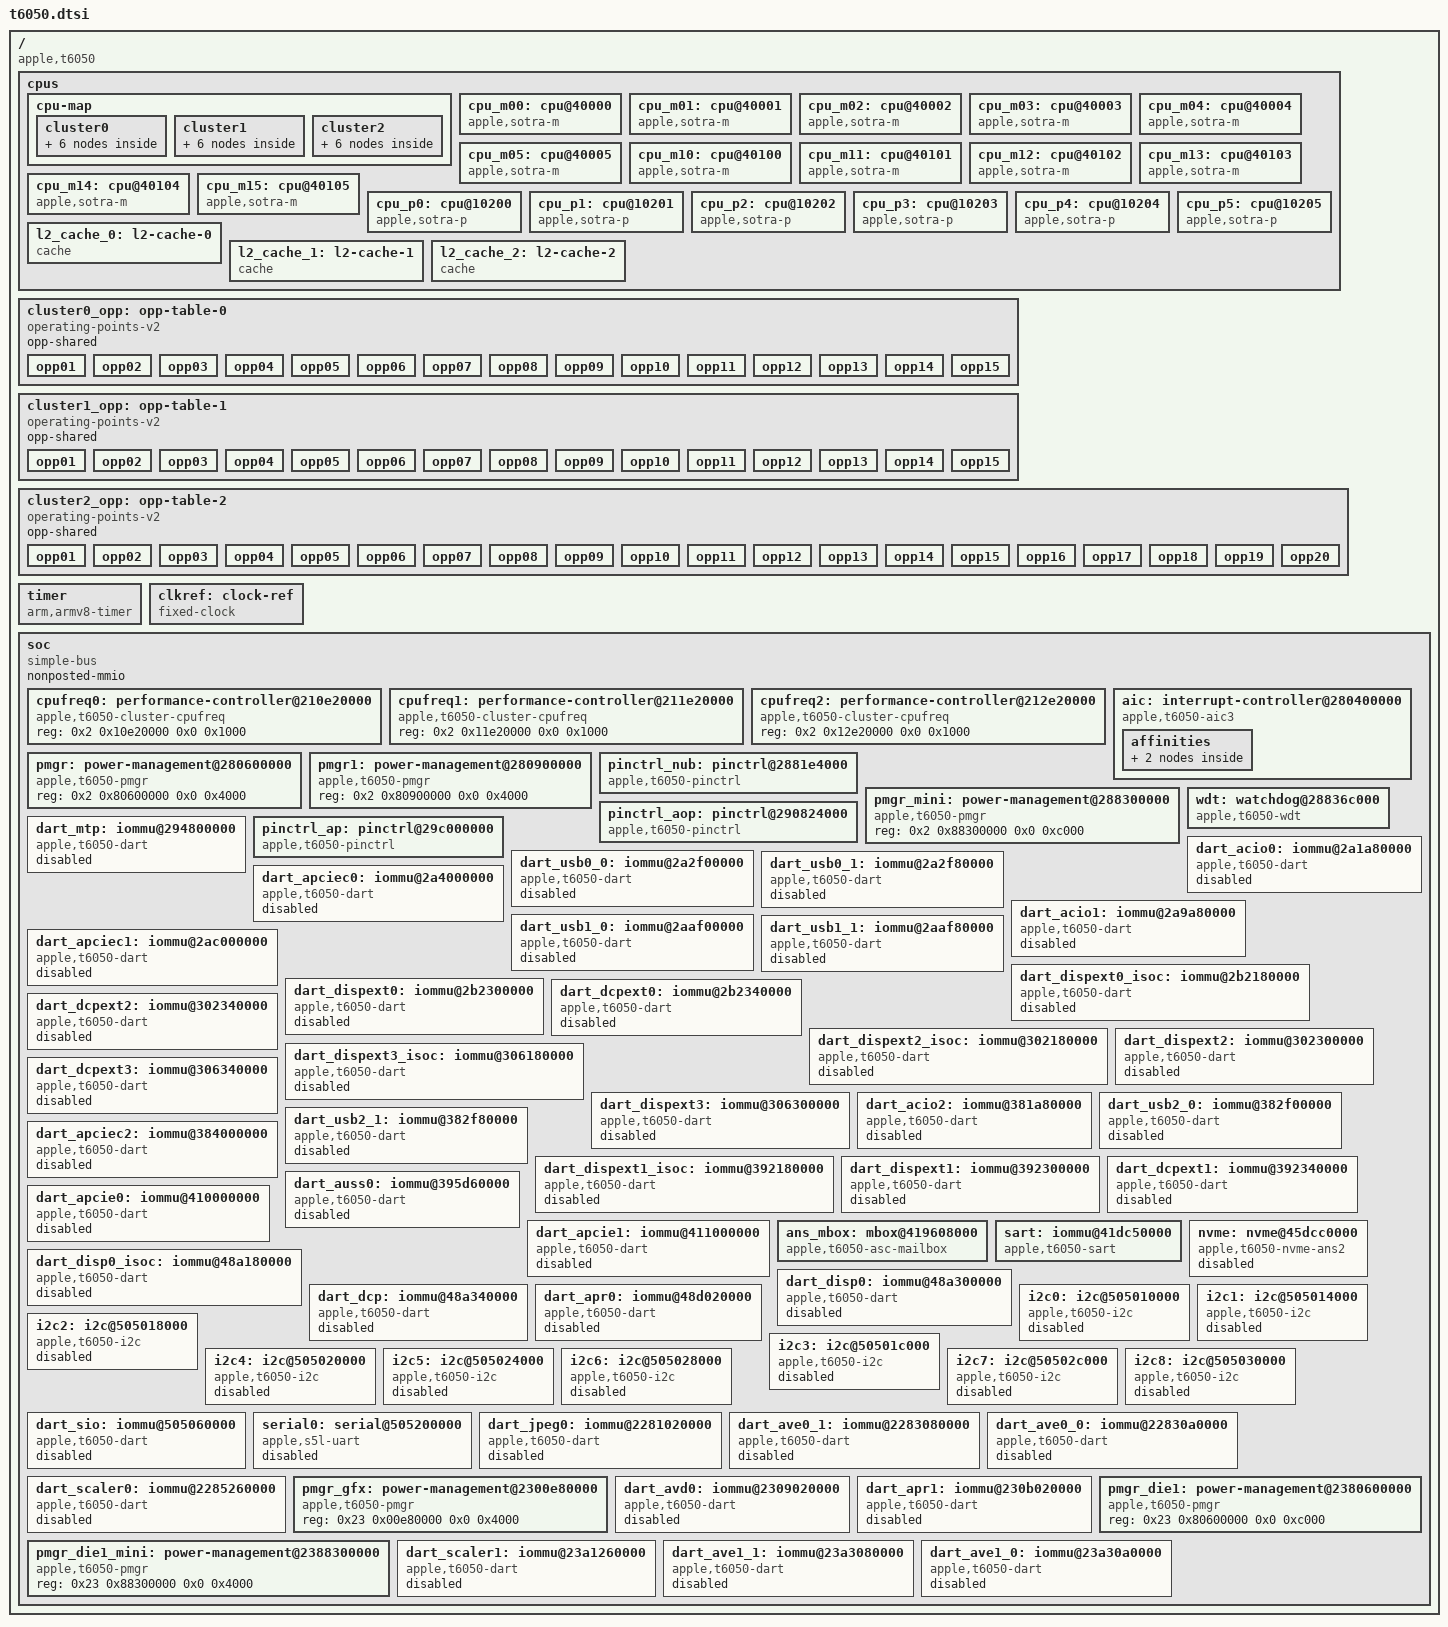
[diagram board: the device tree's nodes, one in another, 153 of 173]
// SPDX-License-Identifier: GPL-2.0+ OR MIT
/*
 * Apple t6050 "M5 Max" SoC - DRAFT device tree.
 *
 * Generated by kernel/experiments/t6050-dt/gen_t6050_dt.py from a sanitized
 * macOS ADT capture of a Mac17,6 (J716c).  UNTESTED: never booted.  See
 * README.md and kernel/native-enablement/plan.md for evidence labels.
 */

#include <dt-bindings/interrupt-controller/apple-aic.h>
#include <dt-bindings/interrupt-controller/irq.h>
#include <dt-bindings/pinctrl/apple.h>

/ {
	compatible = "apple,t6050", "apple,arm-platform";
	#address-cells = <2>;
	#size-cells = <2>;

	cpus {
		#address-cells = <2>;
		#size-cells = <0>;

		cpu-map {
			cluster0 {
				core0 {
					cpu = <&cpu_m00>;
				};
				core1 {
					cpu = <&cpu_m01>;
				};
				core2 {
					cpu = <&cpu_m02>;
				};
				core3 {
					cpu = <&cpu_m03>;
				};
				core4 {
					cpu = <&cpu_m04>;
				};
				core5 {
					cpu = <&cpu_m05>;
				};
			};
			cluster1 {
				core0 {
					cpu = <&cpu_m10>;
				};
				core1 {
					cpu = <&cpu_m11>;
				};
				core2 {
					cpu = <&cpu_m12>;
				};
				core3 {
					cpu = <&cpu_m13>;
				};
				core4 {
					cpu = <&cpu_m14>;
				};
				core5 {
					cpu = <&cpu_m15>;
				};
			};
			cluster2 {
				core0 {
					cpu = <&cpu_p0>;
				};
				core1 {
					cpu = <&cpu_p1>;
				};
				core2 {
					cpu = <&cpu_p2>;
				};
				core3 {
					cpu = <&cpu_p3>;
				};
				core4 {
					cpu = <&cpu_p4>;
				};
				core5 {
					cpu = <&cpu_p5>;
				};
			};
		};

		/* ADT cpu0: cluster 0 type M (apple,sawtooth), ADT reg 0x0; MPIDR per m1n1 5d84c4c3 */
		cpu_m00: cpu@40000 {
			compatible = "apple,sotra-m"; /* placeholder: needs a DT binding */
			device_type = "cpu";
			reg = <0x0 0x40000>;
			enable-method = "spin-table";
			cpu-release-addr = <0 0>; /* filled in by m1n1 */
			next-level-cache = <&l2_cache_0>;
			i-cache-size = <0x20000>;
			d-cache-size = <0x10000>;
			operating-points-v2 = <&cluster0_opp>;
			performance-domains = <&cpufreq0>;
			capacity-dmips-mhz = <768>; /* HYPOTHESIS */
			dynamic-power-coefficient = <550>; /* HYPOTHESIS */
		};

		/* ADT cpu1: cluster 0 type M (apple,sawtooth), ADT reg 0x1; MPIDR per m1n1 5d84c4c3 */
		cpu_m01: cpu@40001 {
			compatible = "apple,sotra-m"; /* placeholder: needs a DT binding */
			device_type = "cpu";
			reg = <0x0 0x40001>;
			enable-method = "spin-table";
			cpu-release-addr = <0 0>; /* filled in by m1n1 */
			next-level-cache = <&l2_cache_0>;
			i-cache-size = <0x20000>;
			d-cache-size = <0x10000>;
			operating-points-v2 = <&cluster0_opp>;
			performance-domains = <&cpufreq0>;
			capacity-dmips-mhz = <768>; /* HYPOTHESIS */
			dynamic-power-coefficient = <550>; /* HYPOTHESIS */
		};

		/* ADT cpu2: cluster 0 type M (apple,sawtooth), ADT reg 0x2; MPIDR per m1n1 5d84c4c3 */
		cpu_m02: cpu@40002 {
			compatible = "apple,sotra-m"; /* placeholder: needs a DT binding */
			device_type = "cpu";
			reg = <0x0 0x40002>;
			enable-method = "spin-table";
			cpu-release-addr = <0 0>; /* filled in by m1n1 */
			next-level-cache = <&l2_cache_0>;
			i-cache-size = <0x20000>;
			d-cache-size = <0x10000>;
			operating-points-v2 = <&cluster0_opp>;
			performance-domains = <&cpufreq0>;
			capacity-dmips-mhz = <768>; /* HYPOTHESIS */
			dynamic-power-coefficient = <550>; /* HYPOTHESIS */
		};

		/* ADT cpu3: cluster 0 type M (apple,sawtooth), ADT reg 0x3; MPIDR per m1n1 5d84c4c3 */
		cpu_m03: cpu@40003 {
			compatible = "apple,sotra-m"; /* placeholder: needs a DT binding */
			device_type = "cpu";
			reg = <0x0 0x40003>;
			enable-method = "spin-table";
			cpu-release-addr = <0 0>; /* filled in by m1n1 */
			next-level-cache = <&l2_cache_0>;
			i-cache-size = <0x20000>;
			d-cache-size = <0x10000>;
			operating-points-v2 = <&cluster0_opp>;
			performance-domains = <&cpufreq0>;
			capacity-dmips-mhz = <768>; /* HYPOTHESIS */
			dynamic-power-coefficient = <550>; /* HYPOTHESIS */
		};

		/* ADT cpu4: cluster 0 type M (apple,sawtooth), ADT reg 0x4; MPIDR per m1n1 5d84c4c3 */
		cpu_m04: cpu@40004 {
			compatible = "apple,sotra-m"; /* placeholder: needs a DT binding */
			device_type = "cpu";
			reg = <0x0 0x40004>;
			enable-method = "spin-table";
			cpu-release-addr = <0 0>; /* filled in by m1n1 */
			next-level-cache = <&l2_cache_0>;
			i-cache-size = <0x20000>;
			d-cache-size = <0x10000>;
			operating-points-v2 = <&cluster0_opp>;
			performance-domains = <&cpufreq0>;
			capacity-dmips-mhz = <768>; /* HYPOTHESIS */
			dynamic-power-coefficient = <550>; /* HYPOTHESIS */
		};

		/* ADT cpu5: cluster 0 type M (apple,sawtooth), ADT reg 0x5; MPIDR per m1n1 5d84c4c3 */
		cpu_m05: cpu@40005 {
			compatible = "apple,sotra-m"; /* placeholder: needs a DT binding */
			device_type = "cpu";
			reg = <0x0 0x40005>;
			enable-method = "spin-table";
			cpu-release-addr = <0 0>; /* filled in by m1n1 */
			next-level-cache = <&l2_cache_0>;
			i-cache-size = <0x20000>;
			d-cache-size = <0x10000>;
			operating-points-v2 = <&cluster0_opp>;
			performance-domains = <&cpufreq0>;
			capacity-dmips-mhz = <768>; /* HYPOTHESIS */
			dynamic-power-coefficient = <550>; /* HYPOTHESIS */
		};

		/* ADT cpu6: cluster 1 type M (apple,sawtooth), ADT reg 0x100; MPIDR per m1n1 5d84c4c3 */
		cpu_m10: cpu@40100 {
			compatible = "apple,sotra-m"; /* placeholder: needs a DT binding */
			device_type = "cpu";
			reg = <0x0 0x40100>;
			enable-method = "spin-table";
			cpu-release-addr = <0 0>; /* filled in by m1n1 */
			next-level-cache = <&l2_cache_1>;
			i-cache-size = <0x20000>;
			d-cache-size = <0x10000>;
			operating-points-v2 = <&cluster1_opp>;
			performance-domains = <&cpufreq1>;
			capacity-dmips-mhz = <768>; /* HYPOTHESIS */
			dynamic-power-coefficient = <550>; /* HYPOTHESIS */
		};

		/* ADT cpu7: cluster 1 type M (apple,sawtooth), ADT reg 0x101; MPIDR per m1n1 5d84c4c3 */
		cpu_m11: cpu@40101 {
			compatible = "apple,sotra-m"; /* placeholder: needs a DT binding */
			device_type = "cpu";
			reg = <0x0 0x40101>;
			enable-method = "spin-table";
			cpu-release-addr = <0 0>; /* filled in by m1n1 */
			next-level-cache = <&l2_cache_1>;
			i-cache-size = <0x20000>;
			d-cache-size = <0x10000>;
			operating-points-v2 = <&cluster1_opp>;
			performance-domains = <&cpufreq1>;
			capacity-dmips-mhz = <768>; /* HYPOTHESIS */
			dynamic-power-coefficient = <550>; /* HYPOTHESIS */
		};

		/* ADT cpu8: cluster 1 type M (apple,sawtooth), ADT reg 0x102; MPIDR per m1n1 5d84c4c3 */
		cpu_m12: cpu@40102 {
			compatible = "apple,sotra-m"; /* placeholder: needs a DT binding */
			device_type = "cpu";
			reg = <0x0 0x40102>;
			enable-method = "spin-table";
			cpu-release-addr = <0 0>; /* filled in by m1n1 */
			next-level-cache = <&l2_cache_1>;
			i-cache-size = <0x20000>;
			d-cache-size = <0x10000>;
			operating-points-v2 = <&cluster1_opp>;
			performance-domains = <&cpufreq1>;
			capacity-dmips-mhz = <768>; /* HYPOTHESIS */
			dynamic-power-coefficient = <550>; /* HYPOTHESIS */
		};

		/* ADT cpu9: cluster 1 type M (apple,sawtooth), ADT reg 0x103; MPIDR per m1n1 5d84c4c3 */
		cpu_m13: cpu@40103 {
			compatible = "apple,sotra-m"; /* placeholder: needs a DT binding */
			device_type = "cpu";
			reg = <0x0 0x40103>;
			enable-method = "spin-table";
			cpu-release-addr = <0 0>; /* filled in by m1n1 */
			next-level-cache = <&l2_cache_1>;
			i-cache-size = <0x20000>;
			d-cache-size = <0x10000>;
			operating-points-v2 = <&cluster1_opp>;
			performance-domains = <&cpufreq1>;
			capacity-dmips-mhz = <768>; /* HYPOTHESIS */
			dynamic-power-coefficient = <550>; /* HYPOTHESIS */
		};

		/* ADT cpu10: cluster 1 type M (apple,sawtooth), ADT reg 0x104; MPIDR per m1n1 5d84c4c3 */
		cpu_m14: cpu@40104 {
			compatible = "apple,sotra-m"; /* placeholder: needs a DT binding */
			device_type = "cpu";
			reg = <0x0 0x40104>;
			enable-method = "spin-table";
			cpu-release-addr = <0 0>; /* filled in by m1n1 */
			next-level-cache = <&l2_cache_1>;
			i-cache-size = <0x20000>;
			d-cache-size = <0x10000>;
			operating-points-v2 = <&cluster1_opp>;
			performance-domains = <&cpufreq1>;
			capacity-dmips-mhz = <768>; /* HYPOTHESIS */
			dynamic-power-coefficient = <550>; /* HYPOTHESIS */
		};

		/* ADT cpu11: cluster 1 type M (apple,sawtooth), ADT reg 0x105; MPIDR per m1n1 5d84c4c3 */
		cpu_m15: cpu@40105 {
			compatible = "apple,sotra-m"; /* placeholder: needs a DT binding */
			device_type = "cpu";
			reg = <0x0 0x40105>;
			enable-method = "spin-table";
			cpu-release-addr = <0 0>; /* filled in by m1n1 */
			next-level-cache = <&l2_cache_1>;
			i-cache-size = <0x20000>;
			d-cache-size = <0x10000>;
			operating-points-v2 = <&cluster1_opp>;
			performance-domains = <&cpufreq1>;
			capacity-dmips-mhz = <768>; /* HYPOTHESIS */
			dynamic-power-coefficient = <550>; /* HYPOTHESIS */
		};

		/* ADT cpu12: cluster 2 type P (apple,everest), ADT reg 0x200; MPIDR per m1n1 5d84c4c3 */
		cpu_p0: cpu@10200 {
			compatible = "apple,sotra-p"; /* placeholder: needs a DT binding */
			device_type = "cpu";
			reg = <0x0 0x10200>;
			enable-method = "spin-table";
			cpu-release-addr = <0 0>; /* filled in by m1n1 */
			next-level-cache = <&l2_cache_2>;
			i-cache-size = <0x30000>;
			d-cache-size = <0x20000>;
			operating-points-v2 = <&cluster2_opp>;
			performance-domains = <&cpufreq2>;
			capacity-dmips-mhz = <1024>; /* HYPOTHESIS */
			dynamic-power-coefficient = <1054>; /* HYPOTHESIS */
		};

		/* ADT cpu13: cluster 2 type P (apple,everest), ADT reg 0x201; MPIDR per m1n1 5d84c4c3 */
		cpu_p1: cpu@10201 {
			compatible = "apple,sotra-p"; /* placeholder: needs a DT binding */
			device_type = "cpu";
			reg = <0x0 0x10201>;
			enable-method = "spin-table";
			cpu-release-addr = <0 0>; /* filled in by m1n1 */
			next-level-cache = <&l2_cache_2>;
			i-cache-size = <0x30000>;
			d-cache-size = <0x20000>;
			operating-points-v2 = <&cluster2_opp>;
			performance-domains = <&cpufreq2>;
			capacity-dmips-mhz = <1024>; /* HYPOTHESIS */
			dynamic-power-coefficient = <1054>; /* HYPOTHESIS */
		};

		/* ADT cpu14: cluster 2 type P (apple,everest), ADT reg 0x202; MPIDR per m1n1 5d84c4c3 */
		cpu_p2: cpu@10202 {
			compatible = "apple,sotra-p"; /* placeholder: needs a DT binding */
			device_type = "cpu";
			reg = <0x0 0x10202>;
			enable-method = "spin-table";
			cpu-release-addr = <0 0>; /* filled in by m1n1 */
			next-level-cache = <&l2_cache_2>;
			i-cache-size = <0x30000>;
			d-cache-size = <0x20000>;
			operating-points-v2 = <&cluster2_opp>;
			performance-domains = <&cpufreq2>;
			capacity-dmips-mhz = <1024>; /* HYPOTHESIS */
			dynamic-power-coefficient = <1054>; /* HYPOTHESIS */
		};

		/* ADT cpu15: cluster 2 type P (apple,everest), ADT reg 0x203; MPIDR per m1n1 5d84c4c3 */
		cpu_p3: cpu@10203 {
			compatible = "apple,sotra-p"; /* placeholder: needs a DT binding */
			device_type = "cpu";
			reg = <0x0 0x10203>;
			enable-method = "spin-table";
			cpu-release-addr = <0 0>; /* filled in by m1n1 */
			next-level-cache = <&l2_cache_2>;
			i-cache-size = <0x30000>;
			d-cache-size = <0x20000>;
			operating-points-v2 = <&cluster2_opp>;
			performance-domains = <&cpufreq2>;
			capacity-dmips-mhz = <1024>; /* HYPOTHESIS */
			dynamic-power-coefficient = <1054>; /* HYPOTHESIS */
		};

		/* ADT cpu16: cluster 2 type P (apple,everest), ADT reg 0x204; MPIDR per m1n1 5d84c4c3 */
		cpu_p4: cpu@10204 {
			compatible = "apple,sotra-p"; /* placeholder: needs a DT binding */
			device_type = "cpu";
			reg = <0x0 0x10204>;
			enable-method = "spin-table";
			cpu-release-addr = <0 0>; /* filled in by m1n1 */
			next-level-cache = <&l2_cache_2>;
			i-cache-size = <0x30000>;
			d-cache-size = <0x20000>;
			operating-points-v2 = <&cluster2_opp>;
			performance-domains = <&cpufreq2>;
			capacity-dmips-mhz = <1024>; /* HYPOTHESIS */
			dynamic-power-coefficient = <1054>; /* HYPOTHESIS */
		};

		/* ADT cpu17: cluster 2 type P (apple,everest), ADT reg 0x205; MPIDR per m1n1 5d84c4c3 */
		cpu_p5: cpu@10205 {
			compatible = "apple,sotra-p"; /* placeholder: needs a DT binding */
			device_type = "cpu";
			reg = <0x0 0x10205>;
			enable-method = "spin-table";
			cpu-release-addr = <0 0>; /* filled in by m1n1 */
			next-level-cache = <&l2_cache_2>;
			i-cache-size = <0x30000>;
			d-cache-size = <0x20000>;
			operating-points-v2 = <&cluster2_opp>;
			performance-domains = <&cpufreq2>;
			capacity-dmips-mhz = <1024>; /* HYPOTHESIS */
			dynamic-power-coefficient = <1054>; /* HYPOTHESIS */
		};

		l2_cache_0: l2-cache-0 {
			compatible = "cache";
			cache-level = <2>;
			cache-unified;
			cache-size = <0x800000>;
		};

		l2_cache_1: l2-cache-1 {
			compatible = "cache";
			cache-level = <2>;
			cache-unified;
			cache-size = <0x800000>;
		};

		l2_cache_2: l2-cache-2 {
			compatible = "cache";
			cache-level = <2>;
			cache-unified;
			cache-size = <0x1000000>;
		};

	};

	/*
	 * Cluster 0 DVFS states from ADT pmgr voltage-states22(-sram), selected by
	 * pmgr acc-clusters.  opp-level = table index + 1 (HYPOTHESIS, M1-M3
	 * convention); opp-microvolt = core rail, only used by the energy model.
	 * clock-latency-ns is a PLACEHOLDER (not measured).
	 */
	cluster0_opp: opp-table-0 {
		compatible = "operating-points-v2";
		opp-shared;

		opp01 {
			opp-hz = /bits/ 64 <1344000000>;
			opp-level = <1>;
			opp-microvolt = <600000>;
			clock-latency-ns = <50000>;
		};
		opp02 {
			opp-hz = /bits/ 64 <1644000000>;
			opp-level = <2>;
			opp-microvolt = <635000>;
			clock-latency-ns = <50000>;
		};
		opp03 {
			opp-hz = /bits/ 64 <1992000000>;
			opp-level = <3>;
			opp-microvolt = <665000>;
			clock-latency-ns = <50000>;
		};
		opp04 {
			opp-hz = /bits/ 64 <2304000000>;
			opp-level = <4>;
			opp-microvolt = <690000>;
			clock-latency-ns = <50000>;
		};
		opp05 {
			opp-hz = /bits/ 64 <2652000000>;
			opp-level = <5>;
			opp-microvolt = <740000>;
			clock-latency-ns = <50000>;
		};
		opp06 {
			opp-hz = /bits/ 64 <2964000000>;
			opp-level = <6>;
			opp-microvolt = <760000>;
			clock-latency-ns = <50000>;
		};
		opp07 {
			opp-hz = /bits/ 64 <3240000000>;
			opp-level = <7>;
			opp-microvolt = <800000>;
			clock-latency-ns = <50000>;
		};
		opp08 {
			opp-hz = /bits/ 64 <3504000000>;
			opp-level = <8>;
			opp-microvolt = <840000>;
			clock-latency-ns = <50000>;
		};
		opp09 {
			opp-hz = /bits/ 64 <3696000000>;
			opp-level = <9>;
			opp-microvolt = <880000>;
			clock-latency-ns = <50000>;
		};
		opp10 {
			opp-hz = /bits/ 64 <3876000000>;
			opp-level = <10>;
			opp-microvolt = <900000>;
			clock-latency-ns = <50000>;
		};
		opp11 {
			opp-hz = /bits/ 64 <4044000000>;
			opp-level = <11>;
			opp-microvolt = <970000>;
			clock-latency-ns = <50000>;
		};
		opp12 {
			opp-hz = /bits/ 64 <4176000000>;
			opp-level = <12>;
			opp-microvolt = <995000>;
			clock-latency-ns = <50000>;
		};
		opp13 {
			opp-hz = /bits/ 64 <4284000000>;
			opp-level = <13>;
			opp-microvolt = <1015000>;
			clock-latency-ns = <50000>;
		};
		opp14 {
			opp-hz = /bits/ 64 <4308000000>;
			opp-level = <14>;
			opp-microvolt = <1015000>;
			clock-latency-ns = <50000>;
		};
		opp15 {
			opp-hz = /bits/ 64 <4380000000>;
			opp-level = <15>;
			opp-microvolt = <1015000>;
			clock-latency-ns = <50000>;
		};
	};

	/*
	 * Cluster 1 DVFS states from ADT pmgr voltage-states23(-sram), selected by
	 * pmgr acc-clusters.  opp-level = table index + 1 (HYPOTHESIS, M1-M3
	 * convention); opp-microvolt = core rail, only used by the energy model.
	 * clock-latency-ns is a PLACEHOLDER (not measured).
	 */
	cluster1_opp: opp-table-1 {
		compatible = "operating-points-v2";
		opp-shared;

		opp01 {
			opp-hz = /bits/ 64 <1344000000>;
			opp-level = <1>;
			opp-microvolt = <600000>;
			clock-latency-ns = <50000>;
		};
		opp02 {
			opp-hz = /bits/ 64 <1644000000>;
			opp-level = <2>;
			opp-microvolt = <635000>;
			clock-latency-ns = <50000>;
		};
		opp03 {
			opp-hz = /bits/ 64 <1992000000>;
			opp-level = <3>;
			opp-microvolt = <665000>;
			clock-latency-ns = <50000>;
		};
		opp04 {
			opp-hz = /bits/ 64 <2304000000>;
			opp-level = <4>;
			opp-microvolt = <690000>;
			clock-latency-ns = <50000>;
		};
		opp05 {
			opp-hz = /bits/ 64 <2652000000>;
			opp-level = <5>;
			opp-microvolt = <740000>;
			clock-latency-ns = <50000>;
		};
		opp06 {
			opp-hz = /bits/ 64 <2964000000>;
			opp-level = <6>;
			opp-microvolt = <760000>;
			clock-latency-ns = <50000>;
		};
		opp07 {
			opp-hz = /bits/ 64 <3240000000>;
			opp-level = <7>;
			opp-microvolt = <800000>;
			clock-latency-ns = <50000>;
		};
		opp08 {
			opp-hz = /bits/ 64 <3504000000>;
			opp-level = <8>;
			opp-microvolt = <840000>;
			clock-latency-ns = <50000>;
		};
		opp09 {
			opp-hz = /bits/ 64 <3696000000>;
			opp-level = <9>;
			opp-microvolt = <880000>;
			clock-latency-ns = <50000>;
		};
		opp10 {
			opp-hz = /bits/ 64 <3876000000>;
			opp-level = <10>;
			opp-microvolt = <900000>;
			clock-latency-ns = <50000>;
		};
		opp11 {
			opp-hz = /bits/ 64 <4044000000>;
			opp-level = <11>;
			opp-microvolt = <970000>;
			clock-latency-ns = <50000>;
		};
		opp12 {
			opp-hz = /bits/ 64 <4176000000>;
			opp-level = <12>;
			opp-microvolt = <1005000>;
			clock-latency-ns = <50000>;
		};
		opp13 {
			opp-hz = /bits/ 64 <4284000000>;
			opp-level = <13>;
			opp-microvolt = <1025000>;
			clock-latency-ns = <50000>;
		};
		opp14 {
			opp-hz = /bits/ 64 <4308000000>;
			opp-level = <14>;
			opp-microvolt = <1025000>;
			clock-latency-ns = <50000>;
		};
		opp15 {
			opp-hz = /bits/ 64 <4380000000>;
			opp-level = <15>;
			opp-microvolt = <1025000>;
			clock-latency-ns = <50000>;
		};
	};

	/*
	 * Cluster 2 DVFS states from ADT pmgr voltage-states5(-sram), selected by
	 * pmgr acc-clusters.  opp-level = table index + 1 (HYPOTHESIS, M1-M3
	 * convention); opp-microvolt = core rail, only used by the energy model.
	 * clock-latency-ns is a PLACEHOLDER (not measured).
	 */
	cluster2_opp: opp-table-2 {
		compatible = "operating-points-v2";
		opp-shared;

		opp01 {
			opp-hz = /bits/ 64 <1308000000>;
			opp-level = <1>;
			opp-microvolt = <625000>;
			clock-latency-ns = <50000>;
		};
		opp02 {
			opp-hz = /bits/ 64 <1620000000>;
			opp-level = <2>;
			opp-microvolt = <675000>;
			clock-latency-ns = <50000>;
		};
		opp03 {
			opp-hz = /bits/ 64 <1980000000>;
			opp-level = <3>;
			opp-microvolt = <700000>;
			clock-latency-ns = <50000>;
		};
		opp04 {
			opp-hz = /bits/ 64 <2292000000>;
			opp-level = <4>;
			opp-microvolt = <735000>;
			clock-latency-ns = <50000>;
		};
		opp05 {
			opp-hz = /bits/ 64 <2580000000>;
			opp-level = <5>;
			opp-microvolt = <775000>;
			clock-latency-ns = <50000>;
		};
		opp06 {
			opp-hz = /bits/ 64 <2880000000>;
			opp-level = <6>;
			opp-microvolt = <810000>;
			clock-latency-ns = <50000>;
		};
		opp07 {
			opp-hz = /bits/ 64 <3180000000>;
			opp-level = <7>;
			opp-microvolt = <840000>;
			clock-latency-ns = <50000>;
		};
		opp08 {
			opp-hz = /bits/ 64 <3432000000>;
			opp-level = <8>;
			opp-microvolt = <875000>;
			clock-latency-ns = <50000>;
		};
		opp09 {
			opp-hz = /bits/ 64 <3648000000>;
			opp-level = <9>;
			opp-microvolt = <890000>;
			clock-latency-ns = <50000>;
		};
		opp10 {
			opp-hz = /bits/ 64 <3828000000>;
			opp-level = <10>;
			opp-microvolt = <925000>;
			clock-latency-ns = <50000>;
		};
		opp11 {
			opp-hz = /bits/ 64 <3984000000>;
			opp-level = <11>;
			opp-microvolt = <960000>;
			clock-latency-ns = <50000>;
		};
		opp12 {
			opp-hz = /bits/ 64 <4104000000>;
			opp-level = <12>;
			opp-microvolt = <980000>;
			clock-latency-ns = <50000>;
		};
		opp13 {
			opp-hz = /bits/ 64 <4188000000>;
			opp-level = <13>;
			opp-microvolt = <1030000>;
			clock-latency-ns = <50000>;
		};
		opp14 {
			opp-hz = /bits/ 64 <4236000000>;
			opp-level = <14>;
			opp-microvolt = <1030000>;
			clock-latency-ns = <50000>;
		};
		opp15 {
			opp-hz = /bits/ 64 <4284000000>;
			opp-level = <15>;
			opp-microvolt = <1030000>;
			clock-latency-ns = <50000>;
		};
		opp16 {
			opp-hz = /bits/ 64 <4308000000>;
			opp-level = <16>;
			opp-microvolt = <1030000>;
			clock-latency-ns = <50000>;
		};
		opp17 {
			opp-hz = /bits/ 64 <4332000000>;
			opp-level = <17>;
			opp-microvolt = <1030000>;
			clock-latency-ns = <50000>;
		};
		opp18 {
			opp-hz = /bits/ 64 <4428000000>;
			opp-level = <18>;
			opp-microvolt = <1030000>;
			clock-latency-ns = <50000>;
		};
		opp19 {
			opp-hz = /bits/ 64 <4512000000>;
			opp-level = <19>;
			opp-microvolt = <1090000>;
			clock-latency-ns = <50000>;
		};
		opp20 {
			opp-hz = /bits/ 64 <4608000000>;
			opp-level = <20>;
			opp-microvolt = <1090000>;
			clock-latency-ns = <50000>;
		};
	};

	timer {
		compatible = "arm,armv8-timer";
		interrupt-parent = <&aic>;
		interrupt-names = "phys", "virt", "hyp-phys", "hyp-virt";
		interrupts = <AIC_FIQ AIC_TMR_GUEST_PHYS IRQ_TYPE_LEVEL_HIGH>,
			     <AIC_FIQ AIC_TMR_GUEST_VIRT IRQ_TYPE_LEVEL_HIGH>,
			     <AIC_FIQ AIC_TMR_HV_PHYS IRQ_TYPE_LEVEL_HIGH>,
			     <AIC_FIQ AIC_TMR_HV_VIRT IRQ_TYPE_LEVEL_HIGH>;
	};

	clkref: clock-ref {
		compatible = "fixed-clock";
		#clock-cells = <0>;
		clock-frequency = <24000000>;
		clock-output-names = "clkref";
	};

	soc: soc {
		compatible = "simple-bus";
		#address-cells = <2>;
		#size-cells = <2>;
		ranges;
		nonposted-mmio;

		/* ADT pmgr reg entry 0x210e20000 (+0x12e8); same address pattern as the M1-M3
		 * cluster DVFS blocks (LIKELY; register format unverified on t6050).  15 states
		 * -> t8112-style 5-bit pstate field (as Asahi uses for M2/M3). */
		cpufreq0: performance-controller@210e20000 {
			compatible = "apple,t6050-cluster-cpufreq", "apple,t8112-cluster-cpufreq";
			reg = <0x2 0x10e20000 0x0 0x1000>;
			#performance-domain-cells = <0>;
		};

		/* ADT pmgr reg entry 0x211e20000 (+0x12e8); same address pattern as the M1-M3
		 * cluster DVFS blocks (LIKELY; register format unverified on t6050).  15 states
		 * -> t8112-style 5-bit pstate field (as Asahi uses for M2/M3). */
		cpufreq1: performance-controller@211e20000 {
			compatible = "apple,t6050-cluster-cpufreq", "apple,t8112-cluster-cpufreq";
			reg = <0x2 0x11e20000 0x0 0x1000>;
			#performance-domain-cells = <0>;
		};

		/* ADT pmgr reg entry 0x212e20000 (+0x12e8); same address pattern as the M1-M3
		 * cluster DVFS blocks (LIKELY; register format unverified on t6050).  20 states
		 * -> t8112-style 5-bit pstate field (as Asahi uses for M2/M3). */
		cpufreq2: performance-controller@212e20000 {
			compatible = "apple,t6050-cluster-cpufreq", "apple,t8112-cluster-cpufreq";
			reg = <0x2 0x12e20000 0x0 0x1000>;
			#performance-domain-cells = <0>;
		};

		/* ADT aic: aic,3 rev 11, core size 0x1cc000 (= t8122/t8132 AIC3).  IRQ_CFG at
		 * +extint-baseaddress 0x10000 and per-die stride 0x4a00 (= 4096 IRQs)
		 * match the Linux AIC3 layout.  ADT aic-numdies-per-die = 2: whether
		 * die-1 (GPU die) IRQs need 4-cell specifiers is UNKNOWN. */
		aic: interrupt-controller@280400000 {
			compatible = "apple,t6050-aic3", "apple,t8122-aic3";
			#interrupt-cells = <3>;
			interrupt-controller;
			reg = <0x2 0x80400000 0x0 0x1cc000>,
			      <0x2 0x80440000 0x0 0x4000>;
			reg-names = "core", "event";
			power-domains = <&ps_aic>;

			affinities {
				m-core-pmu-affinity {
					apple,fiq-index = <AIC_CPU_PMU_E>;
					cpus = <&cpu_m00 &cpu_m01 &cpu_m02 &cpu_m03 &cpu_m04 &cpu_m05 &cpu_m10 &cpu_m11 &cpu_m12 &cpu_m13 &cpu_m14 &cpu_m15>;
				};

				p-core-pmu-affinity {
					apple,fiq-index = <AIC_CPU_PMU_P>;
					cpus = <&cpu_p0 &cpu_p1 &cpu_p2 &cpu_p3 &cpu_p4 &cpu_p5>;
				};
			};
		};

		/* ADT pmgr ps-groups[0] -> pmgr reg[0] */
		pmgr: power-management@280600000 {
			compatible = "apple,t6050-pmgr", "apple,t8103-pmgr", "syscon", "simple-mfd";
			#address-cells = <1>;
			#size-cells = <1>;
			reg = <0x2 0x80600000 0x0 0x4000>;
			/* child nodes are added in t6050-pmgr.dtsi */
		};

		/* ADT pmgr ps-groups[1] -> pmgr reg[1] */
		pmgr1: power-management@280900000 {
			compatible = "apple,t6050-pmgr", "apple,t8103-pmgr", "syscon", "simple-mfd";
			#address-cells = <1>;
			#size-cells = <1>;
			reg = <0x2 0x80900000 0x0 0x4000>;
			/* child nodes are added in t6050-pmgr.dtsi */
		};

		pinctrl_nub: pinctrl@2881e4000 {
			compatible = "apple,t6050-pinctrl", "apple,t8103-pinctrl";
			reg = <0x2 0x881e4000 0x0 0x4000>;
			power-domains = <&ps_nub_gpio>;

			gpio-controller;
			#gpio-cells = <2>;
			gpio-ranges = <&pinctrl_nub 0 0 61>;
			apple,npins = <61>;

			interrupt-controller;
			#interrupt-cells = <2>;
			interrupt-parent = <&aic>;
			interrupts = <AIC_IRQ 706 IRQ_TYPE_LEVEL_HIGH>,
				     <AIC_IRQ 708 IRQ_TYPE_LEVEL_HIGH>,
				     <AIC_IRQ 710 IRQ_TYPE_LEVEL_HIGH>,
				     <AIC_IRQ 712 IRQ_TYPE_LEVEL_HIGH>,
				     <AIC_IRQ 714 IRQ_TYPE_LEVEL_HIGH>,
				     <AIC_IRQ 716 IRQ_TYPE_LEVEL_HIGH>,
				     <AIC_IRQ 718 IRQ_TYPE_LEVEL_HIGH>;
		};

		/* ADT pmgr ps-groups[2] -> pmgr reg[9] */
		pmgr_mini: power-management@288300000 {
			compatible = "apple,t6050-pmgr", "apple,t8103-pmgr", "syscon", "simple-mfd";
			#address-cells = <1>;
			#size-cells = <1>;
			reg = <0x2 0x88300000 0x0 0xc000>;
			/* child nodes are added in t6050-pmgr.dtsi */
		};

		/* ADT wdt-version 3: m1n1 disarms the secondary watchdog (reg[2]) before
		 * boot.  No PMGR device -> no power-domains (as in Asahi t8132). */
		wdt: watchdog@28836c000 {
			compatible = "apple,t6050-wdt", "apple,t8103-wdt";
			reg = <0x2 0x8836c000 0x0 0x4000>;
			clocks = <&clkref>;
			interrupt-parent = <&aic>;
			interrupts = <AIC_IRQ 721 IRQ_TYPE_LEVEL_HIGH>;
		};

		pinctrl_aop: pinctrl@290824000 {
			compatible = "apple,t6050-pinctrl", "apple,t8103-pinctrl";
			reg = <0x2 0x90824000 0x0 0x4000>;
			/* AOP_GPIO is a virtual PMGR device (AOP-managed): no domain */

			gpio-controller;
			#gpio-cells = <2>;
			gpio-ranges = <&pinctrl_aop 0 0 85>;
			apple,npins = <85>;

			interrupt-controller;
			#interrupt-cells = <2>;
			interrupt-parent = <&aic>;
			interrupts = <AIC_IRQ 568 IRQ_TYPE_LEVEL_HIGH>,
				     <AIC_IRQ 569 IRQ_TYPE_LEVEL_HIGH>,
				     <AIC_IRQ 570 IRQ_TYPE_LEVEL_HIGH>,
				     <AIC_IRQ 571 IRQ_TYPE_LEVEL_HIGH>,
				     <AIC_IRQ 572 IRQ_TYPE_LEVEL_HIGH>,
				     <AIC_IRQ 573 IRQ_TYPE_LEVEL_HIGH>,
				     <AIC_IRQ 574 IRQ_TYPE_LEVEL_HIGH>;
		};

		dart_mtp: iommu@294800000 {
			compatible = "apple,t6050-dart", "apple,t8110-dart";
			reg = <0x2 0x94800000 0x0 0xc000>;
			#iommu-cells = <1>;
			interrupt-parent = <&aic>;
			interrupts = <AIC_IRQ 659 IRQ_TYPE_LEVEL_HIGH>;
			/* TODO: power-domains (no ADT clock-gates) */
			status = "disabled"; /* DRAFT: ADT dart-mtp DART instance 0 */
		};

		pinctrl_ap: pinctrl@29c000000 {
			compatible = "apple,t6050-pinctrl", "apple,t8103-pinctrl";
			reg = <0x2 0x9c000000 0x0 0x44000>;
			power-domains = <&ps_gpio>;

			gpio-controller;
			#gpio-cells = <2>;
			gpio-ranges = <&pinctrl_ap 0 0 221>;
			apple,npins = <221>;

			interrupt-controller;
			#interrupt-cells = <2>;
			interrupt-parent = <&aic>;
			interrupts = <AIC_IRQ 486 IRQ_TYPE_LEVEL_HIGH>,
				     <AIC_IRQ 487 IRQ_TYPE_LEVEL_HIGH>,
				     <AIC_IRQ 488 IRQ_TYPE_LEVEL_HIGH>,
				     <AIC_IRQ 489 IRQ_TYPE_LEVEL_HIGH>,
				     <AIC_IRQ 490 IRQ_TYPE_LEVEL_HIGH>,
				     <AIC_IRQ 491 IRQ_TYPE_LEVEL_HIGH>,
				     <AIC_IRQ 492 IRQ_TYPE_LEVEL_HIGH>;
		};

		dart_acio0: iommu@2a1a80000 {
			compatible = "apple,t6050-dart", "apple,t8110-dart";
			reg = <0x2 0xa1a80000 0x0 0xc000>;
			#iommu-cells = <1>;
			interrupt-parent = <&aic>;
			interrupts = <AIC_IRQ 1606 IRQ_TYPE_LEVEL_HIGH>;
			/* TODO: power-domains (no ADT clock-gates) */
			status = "disabled"; /* DRAFT: ADT dart-acio0 DART instance 0 */
		};

		dart_usb0_0: iommu@2a2f00000 {
			compatible = "apple,t6050-dart", "apple,t8110-dart";
			reg = <0x2 0xa2f00000 0x0 0xc000>;
			#iommu-cells = <1>;
			interrupt-parent = <&aic>;
			interrupts = <AIC_IRQ 1423 IRQ_TYPE_LEVEL_HIGH>;
			power-domains = <&ps_atc0_usb>; /* ADT clock-gates */
			status = "disabled"; /* DRAFT: ADT dart-usb0 DART instance 0 */
		};

		dart_usb0_1: iommu@2a2f80000 {
			compatible = "apple,t6050-dart", "apple,t8110-dart";
			reg = <0x2 0xa2f80000 0x0 0xc000>;
			#iommu-cells = <1>;
			interrupt-parent = <&aic>;
			interrupts = <AIC_IRQ 1423 IRQ_TYPE_LEVEL_HIGH>;
			power-domains = <&ps_atc0_usb>; /* ADT clock-gates */
			status = "disabled"; /* DRAFT: ADT dart-usb0 DART instance 1 */
		};

		dart_apciec0: iommu@2a4000000 {
			compatible = "apple,t6050-dart", "apple,t8110-dart";
			reg = <0x2 0xa4000000 0x0 0x20000>;
			#iommu-cells = <1>;
			interrupt-parent = <&aic>;
			interrupts = <AIC_IRQ 1406 IRQ_TYPE_LEVEL_HIGH>;
			/* TODO: power-domains (no ADT clock-gates) */
			status = "disabled"; /* DRAFT: ADT dart-apciec0 DART instance 0 */
		};

		dart_acio1: iommu@2a9a80000 {
			compatible = "apple,t6050-dart", "apple,t8110-dart";
			reg = <0x2 0xa9a80000 0x0 0xc000>;
			#iommu-cells = <1>;
			interrupt-parent = <&aic>;
			interrupts = <AIC_IRQ 1638 IRQ_TYPE_LEVEL_HIGH>;
			/* TODO: power-domains (no ADT clock-gates) */
			status = "disabled"; /* DRAFT: ADT dart-acio1 DART instance 0 */
		};

		dart_usb1_0: iommu@2aaf00000 {
			compatible = "apple,t6050-dart", "apple,t8110-dart";
			reg = <0x2 0xaaf00000 0x0 0xc000>;
			#iommu-cells = <1>;
			interrupt-parent = <&aic>;
			interrupts = <AIC_IRQ 1455 IRQ_TYPE_LEVEL_HIGH>;
			power-domains = <&ps_atc1_usb>; /* ADT clock-gates */
			status = "disabled"; /* DRAFT: ADT dart-usb1 DART instance 0 */
		};

		dart_usb1_1: iommu@2aaf80000 {
			compatible = "apple,t6050-dart", "apple,t8110-dart";
			reg = <0x2 0xaaf80000 0x0 0xc000>;
			#iommu-cells = <1>;
			interrupt-parent = <&aic>;
			interrupts = <AIC_IRQ 1455 IRQ_TYPE_LEVEL_HIGH>;
			power-domains = <&ps_atc1_usb>; /* ADT clock-gates */
			status = "disabled"; /* DRAFT: ADT dart-usb1 DART instance 1 */
		};

		dart_apciec1: iommu@2ac000000 {
			compatible = "apple,t6050-dart", "apple,t8110-dart";
			reg = <0x2 0xac000000 0x0 0x20000>;
			#iommu-cells = <1>;
			interrupt-parent = <&aic>;
			interrupts = <AIC_IRQ 1438 IRQ_TYPE_LEVEL_HIGH>;
			/* TODO: power-domains (no ADT clock-gates) */
			status = "disabled"; /* DRAFT: ADT dart-apciec1 DART instance 0 */
		};

		dart_dispext0_isoc: iommu@2b2180000 {
			compatible = "apple,t6050-dart", "apple,t8110-dart";
			reg = <0x2 0xb2180000 0x0 0x20000>;
			#iommu-cells = <1>;
			interrupt-parent = <&aic>;
			interrupts = <AIC_IRQ 1093 IRQ_TYPE_LEVEL_HIGH>;
			/* TODO: power-domains (no ADT clock-gates) */
			status = "disabled"; /* DRAFT: ADT dart-dispext0-isoc DART instance 0 */
		};

		dart_dispext0: iommu@2b2300000 {
			compatible = "apple,t6050-dart", "apple,t8110-dart";
			reg = <0x2 0xb2300000 0x0 0xc000>;
			#iommu-cells = <1>;
			interrupt-parent = <&aic>;
			interrupts = <AIC_IRQ 1070 IRQ_TYPE_LEVEL_HIGH>;
			/* TODO: power-domains (no ADT clock-gates) */
			status = "disabled"; /* DRAFT: ADT dart-dispext0 DART instance 0 */
		};

		dart_dcpext0: iommu@2b2340000 {
			compatible = "apple,t6050-dart", "apple,t8110-dart";
			reg = <0x2 0xb2340000 0x0 0x20000>;
			#iommu-cells = <1>;
			interrupt-parent = <&aic>;
			interrupts = <AIC_IRQ 1070 IRQ_TYPE_LEVEL_HIGH>;
			/* TODO: power-domains (no ADT clock-gates) */
			status = "disabled"; /* DRAFT: ADT dart-dcpext0 DART instance 0 */
		};

		dart_dispext2_isoc: iommu@302180000 {
			compatible = "apple,t6050-dart", "apple,t8110-dart";
			reg = <0x3 0x02180000 0x0 0x20000>;
			#iommu-cells = <1>;
			interrupt-parent = <&aic>;
			interrupts = <AIC_IRQ 1237 IRQ_TYPE_LEVEL_HIGH>;
			/* TODO: power-domains (no ADT clock-gates) */
			status = "disabled"; /* DRAFT: ADT dart-dispext2-isoc DART instance 0 */
		};

		dart_dispext2: iommu@302300000 {
			compatible = "apple,t6050-dart", "apple,t8110-dart";
			reg = <0x3 0x02300000 0x0 0xc000>;
			#iommu-cells = <1>;
			interrupt-parent = <&aic>;
			interrupts = <AIC_IRQ 1214 IRQ_TYPE_LEVEL_HIGH>;
			/* TODO: power-domains (no ADT clock-gates) */
			status = "disabled"; /* DRAFT: ADT dart-dispext2 DART instance 0 */
		};

		dart_dcpext2: iommu@302340000 {
			compatible = "apple,t6050-dart", "apple,t8110-dart";
			reg = <0x3 0x02340000 0x0 0x20000>;
			#iommu-cells = <1>;
			interrupt-parent = <&aic>;
			interrupts = <AIC_IRQ 1214 IRQ_TYPE_LEVEL_HIGH>;
			/* TODO: power-domains (no ADT clock-gates) */
			status = "disabled"; /* DRAFT: ADT dart-dcpext2 DART instance 0 */
		};

		dart_dispext3_isoc: iommu@306180000 {
			compatible = "apple,t6050-dart", "apple,t8110-dart";
			reg = <0x3 0x06180000 0x0 0x20000>;
			#iommu-cells = <1>;
			interrupt-parent = <&aic>;
			interrupts = <AIC_IRQ 1309 IRQ_TYPE_LEVEL_HIGH>;
			/* TODO: power-domains (no ADT clock-gates) */
			status = "disabled"; /* DRAFT: ADT dart-dispext3-isoc DART instance 0 */
		};

		dart_dispext3: iommu@306300000 {
			compatible = "apple,t6050-dart", "apple,t8110-dart";
			reg = <0x3 0x06300000 0x0 0xc000>;
			#iommu-cells = <1>;
			interrupt-parent = <&aic>;
			interrupts = <AIC_IRQ 1286 IRQ_TYPE_LEVEL_HIGH>;
			/* TODO: power-domains (no ADT clock-gates) */
			status = "disabled"; /* DRAFT: ADT dart-dispext3 DART instance 0 */
		};

		dart_dcpext3: iommu@306340000 {
			compatible = "apple,t6050-dart", "apple,t8110-dart";
			reg = <0x3 0x06340000 0x0 0x20000>;
			#iommu-cells = <1>;
			interrupt-parent = <&aic>;
			interrupts = <AIC_IRQ 1286 IRQ_TYPE_LEVEL_HIGH>;
			/* TODO: power-domains (no ADT clock-gates) */
			status = "disabled"; /* DRAFT: ADT dart-dcpext3 DART instance 0 */
		};

		dart_acio2: iommu@381a80000 {
			compatible = "apple,t6050-dart", "apple,t8110-dart";
			reg = <0x3 0x81a80000 0x0 0xc000>;
			#iommu-cells = <1>;
			interrupt-parent = <&aic>;
			interrupts = <AIC_IRQ 1670 IRQ_TYPE_LEVEL_HIGH>;
			/* TODO: power-domains (no ADT clock-gates) */
			status = "disabled"; /* DRAFT: ADT dart-acio2 DART instance 0 */
		};

		dart_usb2_0: iommu@382f00000 {
			compatible = "apple,t6050-dart", "apple,t8110-dart";
			reg = <0x3 0x82f00000 0x0 0xc000>;
			#iommu-cells = <1>;
			interrupt-parent = <&aic>;
			interrupts = <AIC_IRQ 1487 IRQ_TYPE_LEVEL_HIGH>;
			power-domains = <&ps_atc2_usb>; /* ADT clock-gates */
			status = "disabled"; /* DRAFT: ADT dart-usb2 DART instance 0 */
		};

		dart_usb2_1: iommu@382f80000 {
			compatible = "apple,t6050-dart", "apple,t8110-dart";
			reg = <0x3 0x82f80000 0x0 0xc000>;
			#iommu-cells = <1>;
			interrupt-parent = <&aic>;
			interrupts = <AIC_IRQ 1487 IRQ_TYPE_LEVEL_HIGH>;
			power-domains = <&ps_atc2_usb>; /* ADT clock-gates */
			status = "disabled"; /* DRAFT: ADT dart-usb2 DART instance 1 */
		};

		dart_apciec2: iommu@384000000 {
			compatible = "apple,t6050-dart", "apple,t8110-dart";
			reg = <0x3 0x84000000 0x0 0x20000>;
			#iommu-cells = <1>;
			interrupt-parent = <&aic>;
			interrupts = <AIC_IRQ 1470 IRQ_TYPE_LEVEL_HIGH>;
			/* TODO: power-domains (no ADT clock-gates) */
			status = "disabled"; /* DRAFT: ADT dart-apciec2 DART instance 0 */
		};

		dart_dispext1_isoc: iommu@392180000 {
			compatible = "apple,t6050-dart", "apple,t8110-dart";
			reg = <0x3 0x92180000 0x0 0x20000>;
			#iommu-cells = <1>;
			interrupt-parent = <&aic>;
			interrupts = <AIC_IRQ 1165 IRQ_TYPE_LEVEL_HIGH>;
			/* TODO: power-domains (no ADT clock-gates) */
			status = "disabled"; /* DRAFT: ADT dart-dispext1-isoc DART instance 0 */
		};

		dart_dispext1: iommu@392300000 {
			compatible = "apple,t6050-dart", "apple,t8110-dart";
			reg = <0x3 0x92300000 0x0 0xc000>;
			#iommu-cells = <1>;
			interrupt-parent = <&aic>;
			interrupts = <AIC_IRQ 1142 IRQ_TYPE_LEVEL_HIGH>;
			/* TODO: power-domains (no ADT clock-gates) */
			status = "disabled"; /* DRAFT: ADT dart-dispext1 DART instance 0 */
		};

		dart_dcpext1: iommu@392340000 {
			compatible = "apple,t6050-dart", "apple,t8110-dart";
			reg = <0x3 0x92340000 0x0 0x20000>;
			#iommu-cells = <1>;
			interrupt-parent = <&aic>;
			interrupts = <AIC_IRQ 1142 IRQ_TYPE_LEVEL_HIGH>;
			/* TODO: power-domains (no ADT clock-gates) */
			status = "disabled"; /* DRAFT: ADT dart-dcpext1 DART instance 0 */
		};

		dart_auss0: iommu@395d60000 {
			compatible = "apple,t6050-dart", "apple,t8110-dart";
			reg = <0x3 0x95d60000 0x0 0xc000>;
			#iommu-cells = <1>;
			interrupt-parent = <&aic>;
			interrupts = <AIC_IRQ 2343 IRQ_TYPE_LEVEL_HIGH>;
			/* TODO: power-domains (no ADT clock-gates) */
			status = "disabled"; /* DRAFT: ADT dart-auss0 DART instance 0 */
		};

		dart_apcie0: iommu@410000000 {
			compatible = "apple,t6050-dart", "apple,t8110-dart";
			reg = <0x4 0x10000000 0x0 0x20000>;
			#iommu-cells = <1>;
			interrupt-parent = <&aic>;
			interrupts = <AIC_IRQ 1524 IRQ_TYPE_LEVEL_HIGH>;
			/* TODO: power-domains (no ADT clock-gates) */
			status = "disabled"; /* DRAFT: ADT dart-apcie0 DART instance 0 */
		};

		dart_apcie1: iommu@411000000 {
			compatible = "apple,t6050-dart", "apple,t8110-dart";
			reg = <0x4 0x11000000 0x0 0x20000>;
			#iommu-cells = <1>;
			interrupt-parent = <&aic>;
			interrupts = <AIC_IRQ 1532 IRQ_TYPE_LEVEL_HIGH>;
			/* TODO: power-domains (no ADT clock-gates) */
			status = "disabled"; /* DRAFT: ADT dart-apcie1 DART instance 0 */
		};

		/* ASC mailbox at ans reg[0] + 0x8000 (m1n1 asc.c; works on t6050 in m1n1).
		 * IRQ order sorted from ADT ans interrupts[0..3] (LIKELY, by analogy
		 * with t8103/t6031). */
		ans_mbox: mbox@419608000 {
			compatible = "apple,t6050-asc-mailbox", "apple,asc-mailbox-v4";
			reg = <0x4 0x19608000 0x0 0x4000>;
			interrupt-parent = <&aic>;
			interrupts = <AIC_IRQ 1347 IRQ_TYPE_LEVEL_HIGH>,
				     <AIC_IRQ 1348 IRQ_TYPE_LEVEL_HIGH>,
				     <AIC_IRQ 1349 IRQ_TYPE_LEVEL_HIGH>,
				     <AIC_IRQ 1350 IRQ_TYPE_LEVEL_HIGH>;
			interrupt-names = "send-empty", "send-not-empty",
					  "recv-empty", "recv-not-empty";
			power-domains = <&ps_ans>;
			#mbox-cells = <0>;
		};

		/* ADT sart-ans: sart,coastguard, sart-version 4 (m1n1 SARTv4, 9bfdf8ae).
		 * Needs kernel/patches/t6050/0001 (no fallback: new register layout). */
		sart: iommu@41dc50000 {
			compatible = "apple,t6050-sart";
			reg = <0x4 0x1dc50000 0x0 0xc000>;
			power-domains = <&ps_ans>;
		};

		/* ADT ans: iop,ascwrap-v6, nvme-secure-bar present -> M4+ layout (m1n1
		 * 53f8ee9b): NVMe regs = reg[9], NVMMU regs = reg[3].  The nvme window is
		 * 0x40000 because m1n1 accesses +0x24908..0x24910 through reg[9] although
		 * the ADT size is 0x10000 (LIKELY).  IRQ = interrupts[nvme-interrupt-idx=4].
		 * Needs kernel/patches/t6050/0003. */
		nvme: nvme@45dcc0000 {
			compatible = "apple,t6050-nvme-ans2", "apple,t8132-nvme-ans2";
			reg = <0x4 0x5dcc0000 0x0 0x40000>,
			      <0x4 0x19600000 0x0 0x4000>,
			      <0x4 0x1dcc0000 0x0 0x60010>;
			reg-names = "nvme", "ans", "nvmmu";
			interrupt-parent = <&aic>;
			interrupts = <AIC_IRQ 2338 IRQ_TYPE_LEVEL_HIGH>;
			mboxes = <&ans_mbox>;
			apple,sart = <&sart>;
			power-domains = <&ps_ans>, <&ps_apcie_sys_st0>, <&ps_apcie_sys_st1>;
			power-domain-names = "ans", "apcie0", "apcie1";
			resets = <&ps_ans>;
			status = "disabled"; /* DRAFT */
		};

		dart_disp0_isoc: iommu@48a180000 {
			compatible = "apple,t6050-dart", "apple,t8110-dart";
			reg = <0x4 0x8a180000 0x0 0x20000>;
			#iommu-cells = <1>;
			interrupt-parent = <&aic>;
			interrupts = <AIC_IRQ 1013 IRQ_TYPE_LEVEL_HIGH>;
			/* TODO: power-domains (no ADT clock-gates) */
			status = "disabled"; /* DRAFT: ADT dart-disp0-isoc DART instance 0 */
		};

		dart_disp0: iommu@48a300000 {
			compatible = "apple,t6050-dart", "apple,t8110-dart";
			reg = <0x4 0x8a300000 0x0 0xc000>;
			#iommu-cells = <1>;
			interrupt-parent = <&aic>;
			interrupts = <AIC_IRQ 990 IRQ_TYPE_LEVEL_HIGH>;
			/* TODO: power-domains (no ADT clock-gates) */
			status = "disabled"; /* DRAFT: ADT dart-disp0 DART instance 0 */
		};

		dart_dcp: iommu@48a340000 {
			compatible = "apple,t6050-dart", "apple,t8110-dart";
			reg = <0x4 0x8a340000 0x0 0x20000>;
			#iommu-cells = <1>;
			interrupt-parent = <&aic>;
			interrupts = <AIC_IRQ 990 IRQ_TYPE_LEVEL_HIGH>;
			/* TODO: power-domains (no ADT clock-gates) */
			status = "disabled"; /* DRAFT: ADT dart-dcp DART instance 0 */
		};

		dart_apr0: iommu@48d020000 {
			compatible = "apple,t6050-dart", "apple,t8110-dart";
			reg = <0x4 0x8d020000 0x0 0xc000>;
			#iommu-cells = <1>;
			interrupt-parent = <&aic>;
			interrupts = <AIC_IRQ 1712 IRQ_TYPE_LEVEL_HIGH>;
			power-domains = <&ps_scodec>; /* ADT clock-gates */
			status = "disabled"; /* DRAFT: ADT dart-apr0 DART instance 0 */
		};

		i2c0: i2c@505010000 {
			compatible = "apple,t6050-i2c", "apple,t8103-i2c";
			reg = <0x5 0x05010000 0x0 0x4000>;
			clocks = <&clkref>;
			interrupt-parent = <&aic>;
			interrupts = <AIC_IRQ 1375 IRQ_TYPE_LEVEL_HIGH>;
			#address-cells = <0x1>;
			#size-cells = <0x0>;
			power-domains = <&ps_i2c0>; /* ADT clock-gates */
			status = "disabled";
		};

		i2c1: i2c@505014000 {
			compatible = "apple,t6050-i2c", "apple,t8103-i2c";
			reg = <0x5 0x05014000 0x0 0x4000>;
			clocks = <&clkref>;
			interrupt-parent = <&aic>;
			interrupts = <AIC_IRQ 1376 IRQ_TYPE_LEVEL_HIGH>;
			#address-cells = <0x1>;
			#size-cells = <0x0>;
			power-domains = <&ps_i2c1>; /* ADT clock-gates */
			status = "disabled";
		};

		i2c2: i2c@505018000 {
			compatible = "apple,t6050-i2c", "apple,t8103-i2c";
			reg = <0x5 0x05018000 0x0 0x4000>;
			clocks = <&clkref>;
			interrupt-parent = <&aic>;
			interrupts = <AIC_IRQ 1377 IRQ_TYPE_LEVEL_HIGH>;
			#address-cells = <0x1>;
			#size-cells = <0x0>;
			power-domains = <&ps_i2c2>; /* ADT clock-gates */
			status = "disabled";
		};

		i2c3: i2c@50501c000 {
			compatible = "apple,t6050-i2c", "apple,t8103-i2c";
			reg = <0x5 0x0501c000 0x0 0x4000>;
			clocks = <&clkref>;
			interrupt-parent = <&aic>;
			interrupts = <AIC_IRQ 1378 IRQ_TYPE_LEVEL_HIGH>;
			#address-cells = <0x1>;
			#size-cells = <0x0>;
			power-domains = <&ps_i2c3>; /* ADT clock-gates */
			status = "disabled";
		};

		i2c4: i2c@505020000 {
			compatible = "apple,t6050-i2c", "apple,t8103-i2c";
			reg = <0x5 0x05020000 0x0 0x4000>;
			clocks = <&clkref>;
			interrupt-parent = <&aic>;
			interrupts = <AIC_IRQ 1379 IRQ_TYPE_LEVEL_HIGH>;
			#address-cells = <0x1>;
			#size-cells = <0x0>;
			power-domains = <&ps_i2c4>; /* ADT clock-gates */
			status = "disabled";
		};

		i2c5: i2c@505024000 {
			compatible = "apple,t6050-i2c", "apple,t8103-i2c";
			reg = <0x5 0x05024000 0x0 0x4000>;
			clocks = <&clkref>;
			interrupt-parent = <&aic>;
			interrupts = <AIC_IRQ 1380 IRQ_TYPE_LEVEL_HIGH>;
			#address-cells = <0x1>;
			#size-cells = <0x0>;
			power-domains = <&ps_i2c5>; /* ADT clock-gates */
			status = "disabled";
		};

		i2c6: i2c@505028000 {
			compatible = "apple,t6050-i2c", "apple,t8103-i2c";
			reg = <0x5 0x05028000 0x0 0x4000>;
			clocks = <&clkref>;
			interrupt-parent = <&aic>;
			interrupts = <AIC_IRQ 1381 IRQ_TYPE_LEVEL_HIGH>;
			#address-cells = <0x1>;
			#size-cells = <0x0>;
			power-domains = <&ps_i2c6>; /* ADT clock-gates */
			status = "disabled";
		};

		i2c7: i2c@50502c000 {
			compatible = "apple,t6050-i2c", "apple,t8103-i2c";
			reg = <0x5 0x0502c000 0x0 0x4000>;
			clocks = <&clkref>;
			interrupt-parent = <&aic>;
			interrupts = <AIC_IRQ 1382 IRQ_TYPE_LEVEL_HIGH>;
			#address-cells = <0x1>;
			#size-cells = <0x0>;
			power-domains = <&ps_i2c7>; /* ADT clock-gates */
			status = "disabled";
		};

		i2c8: i2c@505030000 {
			compatible = "apple,t6050-i2c", "apple,t8103-i2c";
			reg = <0x5 0x05030000 0x0 0x4000>;
			clocks = <&clkref>;
			interrupt-parent = <&aic>;
			interrupts = <AIC_IRQ 1383 IRQ_TYPE_LEVEL_HIGH>;
			#address-cells = <0x1>;
			#size-cells = <0x0>;
			power-domains = <&ps_i2c8>; /* ADT clock-gates */
			status = "disabled";
		};

		dart_sio: iommu@505060000 {
			compatible = "apple,t6050-dart", "apple,t8110-dart";
			reg = <0x5 0x05060000 0x0 0x20000>;
			#iommu-cells = <1>;
			interrupt-parent = <&aic>;
			interrupts = <AIC_IRQ 1387 IRQ_TYPE_LEVEL_HIGH>;
			power-domains = <&ps_sio>; /* ADT clock-gates */
			status = "disabled"; /* DRAFT: ADT dart-sio DART instance 0 */
		};

		/* Not wired to an external connector on laptops; m1n1 uses the
		 * dockchannel UART over debugusb instead (no Linux driver yet). */
		serial0: serial@505200000 {
			compatible = "apple,s5l-uart";
			reg = <0x5 0x05200000 0x0 0x4000>;
			reg-io-width = <4>;
			interrupt-parent = <&aic>;
			interrupts = <AIC_IRQ 1359 IRQ_TYPE_LEVEL_HIGH>;
			clocks = <&clkref>, <&clkref>;
			clock-names = "uart", "clk_uart_baud0";
			power-domains = <&ps_uart0>; /* ADT clock-gates */
			status = "disabled";
		};

		dart_jpeg0: iommu@2281020000 {
			compatible = "apple,t6050-dart", "apple,t8110-dart";
			reg = <0x22 0x81020000 0x0 0xc000>;
			#iommu-cells = <1>;
			interrupt-parent = <&aic>;
			interrupts = <AIC_IRQ 1356 IRQ_TYPE_LEVEL_HIGH>;
			power-domains = <&ps_jpg>; /* ADT clock-gates */
			status = "disabled"; /* DRAFT: ADT dart-jpeg0 DART instance 0 */
		};

		dart_ave0_1: iommu@2283080000 {
			compatible = "apple,t6050-dart", "apple,t8110-dart";
			reg = <0x22 0x83080000 0x0 0xc000>;
			#iommu-cells = <1>;
			interrupt-parent = <&aic>;
			interrupts = <AIC_IRQ 2432 IRQ_TYPE_LEVEL_HIGH>;
			power-domains = <&ps_venc0_sys>; /* ADT clock-gates */
			status = "disabled"; /* DRAFT: ADT dart-ave0 DART instance 1 */
		};

		dart_ave0_0: iommu@22830a0000 {
			compatible = "apple,t6050-dart", "apple,t8110-dart";
			reg = <0x22 0x830a0000 0x0 0xc000>;
			#iommu-cells = <1>;
			interrupt-parent = <&aic>;
			interrupts = <AIC_IRQ 2432 IRQ_TYPE_LEVEL_HIGH>;
			power-domains = <&ps_venc0_sys>; /* ADT clock-gates */
			status = "disabled"; /* DRAFT: ADT dart-ave0 DART instance 0 */
		};

		dart_scaler0: iommu@2285260000 {
			compatible = "apple,t6050-dart", "apple,t8110-dart";
			reg = <0x22 0x85260000 0x0 0x20000>;
			#iommu-cells = <1>;
			interrupt-parent = <&aic>;
			interrupts = <AIC_IRQ 2469 IRQ_TYPE_LEVEL_HIGH>;
			power-domains = <&ps_msr0>; /* ADT clock-gates */
			status = "disabled"; /* DRAFT: ADT dart-scaler0 DART instance 0 */
		};

		/* ADT pmgr ps-groups[3] -> pmgr reg[51] */
		pmgr_gfx: power-management@2300e80000 {
			compatible = "apple,t6050-pmgr", "apple,t8103-pmgr", "syscon", "simple-mfd";
			#address-cells = <1>;
			#size-cells = <1>;
			reg = <0x23 0x00e80000 0x0 0x4000>;
			/* child nodes are added in t6050-pmgr.dtsi */
		};

		dart_avd0: iommu@2309020000 {
			compatible = "apple,t6050-dart", "apple,t8110-dart";
			reg = <0x23 0x09020000 0x0 0x20000>;
			#iommu-cells = <1>;
			interrupt-parent = <&aic>;
			interrupts = <AIC_IRQ 2424 IRQ_TYPE_LEVEL_HIGH>;
			power-domains = <&ps_avd_sys>; /* ADT clock-gates */
			status = "disabled"; /* DRAFT: ADT dart-avd0 DART instance 0 */
		};

		dart_apr1: iommu@230b020000 {
			compatible = "apple,t6050-dart", "apple,t8110-dart";
			reg = <0x23 0x0b020000 0x0 0xc000>;
			#iommu-cells = <1>;
			interrupt-parent = <&aic>;
			interrupts = <AIC_IRQ 1760 IRQ_TYPE_LEVEL_HIGH>;
			power-domains = <&ps_prores>; /* ADT clock-gates */
			status = "disabled"; /* DRAFT: ADT dart-apr1 DART instance 0 */
		};

		/* ADT pmgr ps-groups[4] -> pmgr reg[46] */
		pmgr_die1: power-management@2380600000 {
			compatible = "apple,t6050-pmgr", "apple,t8103-pmgr", "syscon", "simple-mfd";
			#address-cells = <1>;
			#size-cells = <1>;
			reg = <0x23 0x80600000 0x0 0xc000>;
			/* child nodes are added in t6050-pmgr.dtsi */
		};

		/* ADT pmgr ps-groups[5] -> pmgr reg[49] */
		pmgr_die1_mini: power-management@2388300000 {
			compatible = "apple,t6050-pmgr", "apple,t8103-pmgr", "syscon", "simple-mfd";
			#address-cells = <1>;
			#size-cells = <1>;
			reg = <0x23 0x88300000 0x0 0x4000>;
			/* child nodes are added in t6050-pmgr.dtsi */
		};

		dart_scaler1: iommu@23a1260000 {
			compatible = "apple,t6050-dart", "apple,t8110-dart";
			reg = <0x23 0xa1260000 0x0 0x20000>;
			#iommu-cells = <1>;
			interrupt-parent = <&aic>;
			interrupts = <AIC_IRQ 2493 IRQ_TYPE_LEVEL_HIGH>;
			power-domains = <&ps_msr1>; /* ADT clock-gates */
			status = "disabled"; /* DRAFT: ADT dart-scaler1 DART instance 0 */
		};

		dart_ave1_1: iommu@23a3080000 {
			compatible = "apple,t6050-dart", "apple,t8110-dart";
			reg = <0x23 0xa3080000 0x0 0xc000>;
			#iommu-cells = <1>;
			interrupt-parent = <&aic>;
			interrupts = <AIC_IRQ 2440 IRQ_TYPE_LEVEL_HIGH>;
			power-domains = <&ps_venc1_sys>; /* ADT clock-gates */
			status = "disabled"; /* DRAFT: ADT dart-ave1 DART instance 1 */
		};

		dart_ave1_0: iommu@23a30a0000 {
			compatible = "apple,t6050-dart", "apple,t8110-dart";
			reg = <0x23 0xa30a0000 0x0 0xc000>;
			#iommu-cells = <1>;
			interrupt-parent = <&aic>;
			interrupts = <AIC_IRQ 2440 IRQ_TYPE_LEVEL_HIGH>;
			power-domains = <&ps_venc1_sys>; /* ADT clock-gates */
			status = "disabled"; /* DRAFT: ADT dart-ave1 DART instance 0 */
		};
	};
};

#include "t6050-pmgr.dtsi"
